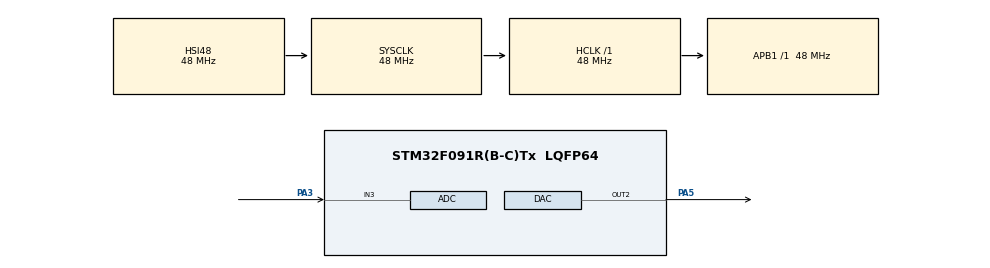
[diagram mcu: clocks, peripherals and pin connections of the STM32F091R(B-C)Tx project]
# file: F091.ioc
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DAC.DAC_OutputBuffer2=DAC_OUTPUTBUFFER_DISABLE
DAC.DAC_Trigger2=DAC_TRIGGER_T6_TRGO
Dma.DAC_CH2.0.Direction=DMA_MEMORY_TO_PERIPH
Dma.DAC_CH2.0.Instance=DMA1_Channel4
Dma.DAC_CH2.0.MemDataAlignment=DMA_MDATAALIGN_HALFWORD
Dma.DAC_CH2.0.MemInc=DMA_MINC_ENABLE
Dma.DAC_CH2.0.Mode=DMA_NORMAL
Dma.DAC_CH2.0.PeriphDataAlignment=DMA_PDATAALIGN_HALFWORD
Dma.DAC_CH2.0.PeriphInc=DMA_PINC_DISABLE
Dma.DAC_CH2.0.Priority=DMA_PRIORITY_LOW
Dma.Request0=DAC_CH2
Mcu.Family=STM32F0
Mcu.Name=STM32F091R(B-C)Tx
Mcu.Package=LQFP64
NVIC.DMA1_Ch4_7_DMA2_Ch3_5_IRQn=true\:0\:0\:false\:false\:true\:false\:true
NVIC.TIM6_DAC_IRQn=true\:0\:0\:false\:false\:true\:true\:true
PA3.Mode=IN3
PA3.Signal=ADC_IN3
PA5.Signal=COMP_DAC2_group
ProjectManager.HeapSize=0x200
ProjectManager.StackSize=0x400
ProjectManager.TargetToolchain=MDK-ARM V5.27
RCC.AHBFreq_Value=48000000
RCC.APB1Freq_Value=48000000
RCC.APB1TimFreq_Value=48000000
RCC.HCLKFreq_Value=48000000
RCC.PLLDivider=RCC_PREDIV_DIV2
RCC.PLLMUL=RCC_PLL_MUL9
RCC.SYSCLKFreq_VALUE=48000000
RCC.SYSCLKSource=RCC_SYSCLKSOURCE_HSI48
SH.COMP_DAC2_group.0=DAC_OUT2,DAC_OUT2
TIM6.AutoReloadPreload=TIM_AUTORELOAD_PRELOAD_ENABLE
TIM6.Period=12-1
TIM6.Prescaler=1000-1
TIM6.TIM_MasterOutputTrigger=TIM_TRGO_UPDATE
VP_TIM6_VS_ClockSourceINT.Mode=Enable_Timer
board=custom

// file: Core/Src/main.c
/* USER CODE BEGIN Header */
/**
  ******************************************************************************
  * @file           : main.c
  * @brief          : Main program body
  ******************************************************************************
  * @attention
  *
  * <h2><center>&copy; Copyright (c) 2021 STMicroelectronics.
  * All rights reserved.</center></h2>
  *
  * This software component is licensed by ST under BSD 3-Clause license,
  * the "License"; You may not use this file except in compliance with the
  * License. You may obtain a copy of the License at:
  *                        opensource.org/licenses/BSD-3-Clause
  *
  ******************************************************************************
  */
/* USER CODE END Header */
#include "main.h"

/* USER CODE BEGIN Includes */
#include "audio.h"
/* USER CODE END Includes */

ADC_HandleTypeDef hadc;

DAC_HandleTypeDef hdac;
DMA_HandleTypeDef hdma_dac_ch2;

TIM_HandleTypeDef htim6;

void SystemClock_Config(void);
static void MX_GPIO_Init(void);
static void MX_DMA_Init(void);
static void MX_DAC_Init(void);
static void MX_ADC_Init(void);
static void MX_TIM6_Init(void);

/* USER CODE BEGIN 0 */
// const uint16_t Sine12bit[100]={
// 0x0800,0x0881,0x0901,0x0980,0x09FD,0x0A79,0x0AF2,0x0B68,0x0BDA,0x0C49,
// 0x0CB3,0x0D19,0x0D79,0x0DD4,0x0E29,0x0E78,0x0EC0,0x0F02,0x0F3C,0x0F6F,
// 0x0F9B,0x0FBF,0x0FDB,0x0FEF,0x0FFB,0x0FFF,0x0FFB,0x0FEF,0x0FDB,0x0FBF,
// 0x0F9B,0x0F6F,0x0F3C,0x0F02,0x0EC0,0x0E78,0x0E29,0x0DD4,0x0D79,0x0D19,
// 0x0CB3,0x0C49,0x0BDA,0x0B68,0x0AF2,0x0A79,0x09FD,0x0980,0x0901,0x0881,
// 0x0800,0x077F,0x06FF,0x0680,0x0603,0x0587,0x050E,0x0498,0x0426,0x03B7,
// 0x034D,0x02E7,0x0287,0x022C,0x01D7,0x0188,0x0140,0x00FE,0x00C4,0x0091,
// 0x0065,0x0041,0x0025,0x0011,0x0005,0x0001,0x0005,0x0011,0x0025,0x0041,
// 0x0065,0x0091,0x00C4,0x00FE,0x0140,0x0188,0x01D7,0x022C,0x0287,0x02E7,
// 0x034D,0x03B7,0x0426,0x0498,0x050E,0x0587,0x0603,0x0680,0x06FF,0x077F,
// };
uint16_t DualSine12bit[100];
/* num:正玄播中采集的点数
 * p:存放数据的数组
 * U:输出电压的峰值(0~1.5V)
 */
#include "math.h"
#define PI (double)3.1415927
void SinWaveData(uint16_t num,uint16_t *p,float U)
{
	uint16_t i;
	for(i=0;i<num;i++)
		*p++ = (uint16_t)((U * sin(( 1.0*i/(num-1))*2*PI)+U)*4095/3.3);
		//D[i] = (u16)((U*sin(( 1.0*i/(num-1))*2*Pi)+U)*4095/3.3);
}
/* USER CODE END 0 */

int main(void)
{

  /* MCU Configuration--------------------------------------------------------*/

  /* Reset of all peripherals, Initializes the Flash interface and the Systick. */
  HAL_Init();

  /* Configure the system clock */
  SystemClock_Config();

  /* Initialize all configured peripherals */
  MX_GPIO_Init();
  MX_DMA_Init();
  MX_DAC_Init();
  MX_ADC_Init();
  MX_TIM6_Init();

  /* Infinite loop */
  /* USER CODE BEGIN WHILE */
	// ADC_IN3/PA3
	// DAC_OUT2/PA5
	volatile uint32_t ADC_Value;
	uint32_t DAC_Val = 0 , i = 0;;
	HAL_ADCEx_Calibration_Start(&hadc);

	SinWaveData(100,DualSine12bit,1.5);
	HAL_TIM_Base_Start(&htim6);
	//HAL_DAC_Start_DMA(&hdac,DAC1_CHANNEL_2,(uint32_t *)DualSine12bit,100/2,DAC_ALIGN_12B_R);
	//HAL_DAC_Start_DMA(&hdac,DAC1_CHANNEL_2,(uint32_t *)audio_dat,sizeof(audio_dat),DAC_ALIGN_12B_R);
  while (1)
  {
		HAL_DAC_Start_DMA(&hdac,DAC1_CHANNEL_2,(uint32_t *)audio_dat,sizeof(audio_dat)/2,DAC_ALIGN_12B_R);
		HAL_Delay(1000);

//		HAL_ADC_Start(&hadc);     //启动ADC转换
//		HAL_ADC_PollForConversion(&hadc, 50);   //等待转换完成�?50为最大等待时间，单位为ms
//		if(HAL_IS_BIT_SET(HAL_ADC_GetState(&hadc), HAL_ADC_STATE_REG_EOC))
//    {
//			ADC_Value = HAL_ADC_GetValue(&hadc);   //获取AD值
//			//printf("PA3 True Voltage value : %.4f \r\n",ADC_Value*3.3f/4096);
//    }
			//HAL_Delay(100);
    /* USER CODE END WHILE */

  }
}

void SystemClock_Config(void)
{
  RCC_OscInitTypeDef RCC_OscInitStruct = {0};
  RCC_ClkInitTypeDef RCC_ClkInitStruct = {0};

  /** Initializes the RCC Oscillators according to the specified parameters
  * in the RCC_OscInitTypeDef structure.
  */
  RCC_OscInitStruct.OscillatorType = RCC_OSCILLATORTYPE_HSI14|RCC_OSCILLATORTYPE_HSI48;
  RCC_OscInitStruct.HSI48State = RCC_HSI48_ON;
  RCC_OscInitStruct.HSI14State = RCC_HSI14_ON;
  RCC_OscInitStruct.HSI14CalibrationValue = 16;
  RCC_OscInitStruct.PLL.PLLState = RCC_PLL_NONE;
  if (HAL_RCC_OscConfig(&RCC_OscInitStruct) != HAL_OK)
  {
    Error_Handler();
  }
  /** Initializes the CPU, AHB and APB buses clocks
  */
  RCC_ClkInitStruct.ClockType = RCC_CLOCKTYPE_HCLK|RCC_CLOCKTYPE_SYSCLK
                              |RCC_CLOCKTYPE_PCLK1;
  RCC_ClkInitStruct.SYSCLKSource = RCC_SYSCLKSOURCE_HSI48;
  RCC_ClkInitStruct.AHBCLKDivider = RCC_SYSCLK_DIV1;
  RCC_ClkInitStruct.APB1CLKDivider = RCC_HCLK_DIV1;

  if (HAL_RCC_ClockConfig(&RCC_ClkInitStruct, FLASH_LATENCY_1) != HAL_OK)
  {
    Error_Handler();
  }
}

static void MX_ADC_Init(void)
{

  ADC_ChannelConfTypeDef sConfig = {0};

  /** Configure the global features of the ADC (Clock, Resolution, Data Alignment and number of conversion)
  */
  hadc.Instance = ADC1;
  hadc.Init.ClockPrescaler = ADC_CLOCK_ASYNC_DIV1;
  hadc.Init.Resolution = ADC_RESOLUTION_12B;
  hadc.Init.DataAlign = ADC_DATAALIGN_RIGHT;
  hadc.Init.ScanConvMode = ADC_SCAN_DIRECTION_FORWARD;
  hadc.Init.EOCSelection = ADC_EOC_SINGLE_CONV;
  hadc.Init.LowPowerAutoWait = DISABLE;
  hadc.Init.LowPowerAutoPowerOff = DISABLE;
  hadc.Init.ContinuousConvMode = DISABLE;
  hadc.Init.DiscontinuousConvMode = DISABLE;
  hadc.Init.ExternalTrigConv = ADC_SOFTWARE_START;
  hadc.Init.ExternalTrigConvEdge = ADC_EXTERNALTRIGCONVEDGE_NONE;
  hadc.Init.DMAContinuousRequests = DISABLE;
  hadc.Init.Overrun = ADC_OVR_DATA_PRESERVED;
  if (HAL_ADC_Init(&hadc) != HAL_OK)
  {
    Error_Handler();
  }
  /** Configure for the selected ADC regular channel to be converted.
  */
  sConfig.Channel = ADC_CHANNEL_3;
  sConfig.Rank = ADC_RANK_CHANNEL_NUMBER;
  sConfig.SamplingTime = ADC_SAMPLETIME_1CYCLE_5;
  if (HAL_ADC_ConfigChannel(&hadc, &sConfig) != HAL_OK)
  {
    Error_Handler();
  }

}

static void MX_DAC_Init(void)
{

  DAC_ChannelConfTypeDef sConfig = {0};

  /** DAC Initialization
  */
  hdac.Instance = DAC;
  if (HAL_DAC_Init(&hdac) != HAL_OK)
  {
    Error_Handler();
  }
  /** DAC channel OUT2 config
  */
  sConfig.DAC_Trigger = DAC_TRIGGER_T6_TRGO;
  sConfig.DAC_OutputBuffer = DAC_OUTPUTBUFFER_DISABLE;
  if (HAL_DAC_ConfigChannel(&hdac, &sConfig, DAC_CHANNEL_2) != HAL_OK)
  {
    Error_Handler();
  }

}

static void MX_TIM6_Init(void)
{

  TIM_MasterConfigTypeDef sMasterConfig = {0};

  /* USER CODE BEGIN TIM6_Init 1 */
	//TIM6频率(Pclk:36M)3K:36000000/1000/12=3000Hz
  //500/12:8K  250/12:16K 125/12:32K 125/6:64K 125/3:128K
  /* USER CODE END TIM6_Init 1 */
  htim6.Instance = TIM6;
  htim6.Init.Prescaler = 125-1;
  htim6.Init.CounterMode = TIM_COUNTERMODE_UP;
  htim6.Init.Period = 12-1;
  htim6.Init.AutoReloadPreload = TIM_AUTORELOAD_PRELOAD_ENABLE;
  if (HAL_TIM_Base_Init(&htim6) != HAL_OK)
  {
    Error_Handler();
  }
  sMasterConfig.MasterOutputTrigger = TIM_TRGO_UPDATE;
  sMasterConfig.MasterSlaveMode = TIM_MASTERSLAVEMODE_DISABLE;
  if (HAL_TIMEx_MasterConfigSynchronization(&htim6, &sMasterConfig) != HAL_OK)
  {
    Error_Handler();
  }

}

static void MX_DMA_Init(void)
{

  /* DMA controller clock enable */
  __HAL_RCC_DMA1_CLK_ENABLE();

  /* DMA interrupt init */
  /* DMA1_Ch4_7_DMA2_Ch3_5_IRQn interrupt configuration */
  HAL_NVIC_SetPriority(DMA1_Ch4_7_DMA2_Ch3_5_IRQn, 0, 0);
  HAL_NVIC_EnableIRQ(DMA1_Ch4_7_DMA2_Ch3_5_IRQn);

}

static void MX_GPIO_Init(void)
{

  /* GPIO Ports Clock Enable */
  __HAL_RCC_GPIOA_CLK_ENABLE();

}

void Error_Handler(void)
{
  __disable_irq();
  while (1)
  {
  }
}

/************************ (C) COPYRIGHT STMicroelectronics *****END OF FILE****/
